AUTOSAR XML (schema 4-3-0)
package /ComponentTypes
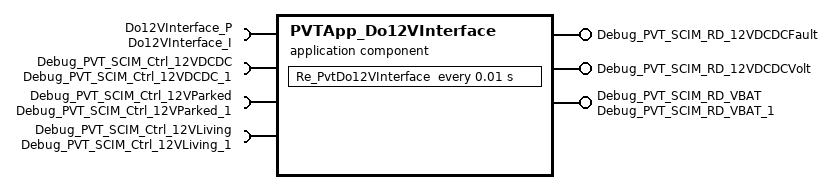
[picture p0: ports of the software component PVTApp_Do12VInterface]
  application sw component type PVTApp_Do12VInterface
    provide port Debug_PVT_SCIM_RD_12VDCDCFault: nonqueued-sender-com-spec{data-element=Debug_PVT_SCIM_RD_12VDCDCFault, init-value=0}, provided-interface=Debug_PVT_SCIM_RD_12VDCDCFault
    provide port Debug_PVT_SCIM_RD_12VDCDCVolt: nonqueued-sender-com-spec{data-element=Debug_PVT_SCIM_RD_12VDCDCVolt, init-value=0}, provided-interface=Debug_PVT_SCIM_RD_12VDCDCVolt
    require port Do12VInterface_P: required-com-specs=[SetDo12VParkedActive, SetDo12VLivingActive, SetDcdc12VActive, GetDo12VPinsState], required-interface=Do12VInterface_I
    provide port Debug_PVT_SCIM_RD_VBAT: nonqueued-sender-com-spec{data-element=Debug_PVT_SCIM_RD_VBAT, init-value=0}, provided-interface=Debug_PVT_SCIM_RD_VBAT_1
    require port Debug_PVT_SCIM_Ctrl_12VDCDC: nonqueued-receiver-com-spec{data-element=Debug_PVT_SCIM_Ctrl_12VDCDC, init-value=0}, required-interface=Debug_PVT_SCIM_Ctrl_12VDCDC_1
    require port Debug_PVT_SCIM_Ctrl_12VParked: nonqueued-receiver-com-spec{data-element=Debug_PVT_SCIM_Ctrl_12VParked, init-value=0}, required-interface=Debug_PVT_SCIM_Ctrl_12VParked_1
    require port Debug_PVT_SCIM_Ctrl_12VLiving: nonqueued-receiver-com-spec{data-element=Debug_PVT_SCIM_Ctrl_12VLiving, init-value=0}, required-interface=Debug_PVT_SCIM_Ctrl_12VLiving_1
    behavior PVTApp_Do12VInterface_InternalBehavior
      timing event TMT_Re_PvtDo12VInterface: start-on-event=Re_PvtDo12VInterface, period=0.01
      runnable Re_PvtDo12VInterface
        data-receive-point-by-values:
          access REC_Debug_PVT_SCIM_Ctrl_12VDCDC_Debug_PVT_SCIM_Ctrl_12VDCDC: accessed-variable=Debug_PVT_SCIM_Ctrl_12VDCDC.Debug_PVT_SCIM_Ctrl_12VDCDC
          access REC_Debug_PVT_SCIM_Ctrl_12VLiving_Debug_PVT_SCIM_Ctrl_12VLiving: accessed-variable=Debug_PVT_SCIM_Ctrl_12VLiving.Debug_PVT_SCIM_Ctrl_12VLiving
          access REC_Debug_PVT_SCIM_Ctrl_12VParked_Debug_PVT_SCIM_Ctrl_12VParked: accessed-variable=Debug_PVT_SCIM_Ctrl_12VParked.Debug_PVT_SCIM_Ctrl_12VParked
        data-send-points:
          access SEND_Debug_PVT_SCIM_RD_12VDCDCFault_Debug_PVT_SCIM_RD_12VDCDCFault: accessed-variable=Debug_PVT_SCIM_RD_12VDCDCFault.Debug_PVT_SCIM_RD_12VDCDCFault
          access SEND_Debug_PVT_SCIM_RD_12VDCDCVolt_Debug_PVT_SCIM_RD_12VDCDCVolt: accessed-variable=Debug_PVT_SCIM_RD_12VDCDCVolt.Debug_PVT_SCIM_RD_12VDCDCVolt
          access SEND_Debug_PVT_SCIM_RD_VBAT_Debug_PVT_SCIM_RD_VBAT: accessed-variable=Debug_PVT_SCIM_RD_VBAT.Debug_PVT_SCIM_RD_VBAT
        4 x sync call:
          SC_Do12VInterface_P_GetDo12VPinsState: operation=Do12VInterface_P.GetDo12VPinsState
          SC_Do12VInterface_P_SetDcdc12VActive: operation=Do12VInterface_P.SetDcdc12VActive
          SC_Do12VInterface_P_SetDo12VLivingActive: operation=Do12VInterface_P.SetDo12VLivingActive
          SC_Do12VInterface_P_SetDo12VParkedActive: operation=Do12VInterface_P.SetDo12VParkedActive
  swc implementation PVTApp_Do12VInterface_Implementation: behavior=PVTApp_Do12VInterface_InternalBehavior
    code-descriptors:
      code Default: artifact-descriptors=autosar-engineering-object=category=SWSRC
